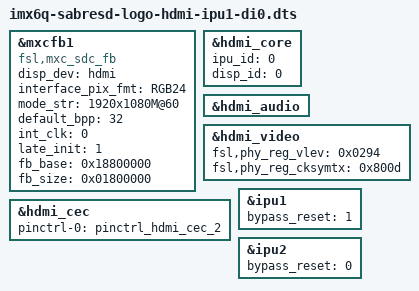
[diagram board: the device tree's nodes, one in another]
/*
 * Copyright (C) 2015 Freescale Semiconductor, Inc.
 *
 * This program is free software; you can redistribute it and/or modify
 * it under the terms of the GNU General Public License version 2 as
 * published by the Free Software Foundation.
 */

#include "imx6q-sabresd.dts"

&mxcfb1 {
	compatible = "fsl,mxc_sdc_fb";
	disp_dev = "hdmi";
	interface_pix_fmt = "RGB24";
	mode_str ="1920x1080M@60";
	default_bpp = <32>;
	int_clk = <0>;
	late_init = <1>;
	fb_base = <0x18800000>;  /* Frame buffer base address, it is same as CONFIG_FB_BASE in Uboot. */
	fb_size = <0x01800000>;  /* Reserved display memory size, bigger than 3 x framer buffer size. */
	status = "okay";
};

&hdmi_core {
	ipu_id = <0>;
	disp_id = <0>;
	status = "okay";
};

&hdmi_audio {
	status = "okay";
};

/* EPT HDMI HDCP */
&hdmi_video {
	/* because i2c2 is used, disable it */
	/* pinctrl-names = "default"; */
	/* pinctrl-0 = <&pinctrl_hdmi_hdcp_1>; */
	/* fsl,hdcp; */

	fsl,phy_reg_vlev = <0x0294>;
	fsl,phy_reg_cksymtx = <0x800d>;
	status = "okay";
};

/* EPT HDMI CEC */
&hdmi_cec {
	pinctrl-names = "default";
	pinctrl-0 = <&pinctrl_hdmi_cec_2>;
	status = "okay";
};

&ipu1 {
	bypass_reset = <1>;
	status = "okay";
};

&ipu2 {
	bypass_reset = <0>;
	status = "okay";
};

